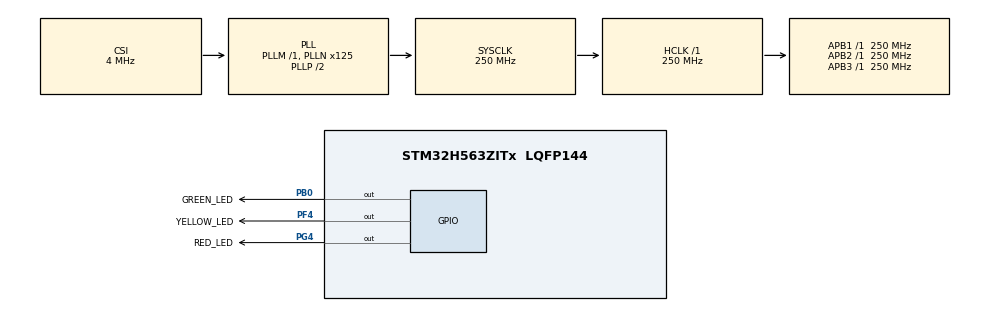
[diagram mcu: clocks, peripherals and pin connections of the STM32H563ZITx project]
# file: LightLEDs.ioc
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CORTEX_M33_NS.userName=CORTEX_M33
Mcu.Family=STM32H5
Mcu.Name=STM32H563ZITx
Mcu.Package=LQFP144
NVIC.PriorityGroup=NVIC_PRIORITYGROUP_4
PB0.GPIO_Label=GREEN_LED
PB0.Signal=GPIO_Output
PF4.GPIO_Label=YELLOW_LED
PF4.Signal=GPIO_Output
PG4.GPIO_Label=RED_LED
PG4.Signal=GPIO_Output
ProjectManager.HeapSize=0x200
ProjectManager.StackSize=0x400
ProjectManager.TargetToolchain=STM32CubeIDE
RCC.ADCFreq_Value=250000000
RCC.AHBFreq_Value=250000000
RCC.APB1Freq_Value=250000000
RCC.APB1TimFreq_Value=250000000
RCC.APB2Freq_Value=250000000
RCC.APB2TimFreq_Value=250000000
RCC.APB3Freq_Value=250000000
RCC.CSI_VALUE=4000000
RCC.CortexFreq_Value=250000000
RCC.EPOD_VALUE=4000000
RCC.HCLKFreq_Value=250000000
RCC.HSE_VALUE=25000000
RCC.HSI48_VALUE=48000000
RCC.HSI_VALUE=64000000
RCC.LSE_VALUE=32768
RCC.LSIRC_VALUE=32000
RCC.PLL2FRACN=0
RCC.PLL3FRACN=0
RCC.PLLFRACN=0
RCC.PLLN=125
RCC.SYSCLKFreq_VALUE=250000000
RCC.SYSCLKSource=RCC_SYSCLKSOURCE_PLLCLK
RCC.USBFreq_Value=48000000
RCC.VCOOutputFreq_Value=500000000
VP_BOOTPATH_VS_BOOTPATH.Mode=BP_Activate
VP_ICACHE_VS_ICACHE.Mode=DirectMappedCache
VP_MEMORYMAP_VS_MEMORYMAP.Mode=CurAppReg
VP_PWR_VS_DBSignals.Mode=DisableDeadBatterySignals
VP_PWR_VS_LPOM.Mode=PowerOptimisation
VP_PWR_VS_SECSignals.Mode=Security/Privilege
board=custom

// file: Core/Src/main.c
/* USER CODE BEGIN Header */
/**
 ******************************************************************************
 * @file           : main.c
 * @brief          : Main program body
 ******************************************************************************
 * @attention
 *
 * Copyright (c) 2023 STMicroelectronics.
 * All rights reserved.
 *
 * This software is licensed under terms that can be found in the LICENSE file
 * in the root directory of this software component.
 * If no LICENSE file comes with this software, it is provided AS-IS.
 *
 ******************************************************************************
 */
/* USER CODE END Header */
#include "main.h"
#include "icache.h"
#include "memorymap.h"
#include "gpio.h"

void SystemClock_Config(void);

int main(void)
{

  /* MCU Configuration--------------------------------------------------------*/

  /* Reset of all peripherals, Initializes the Flash interface and the Systick. */
  HAL_Init();

  /* Configure the system clock */
  SystemClock_Config();

  /* Initialize all configured peripherals */
  MX_GPIO_Init();
  MX_MEMORYMAP_Init();
  MX_ICACHE_Init();

  /* Infinite loop */
  /* USER CODE BEGIN WHILE */
	while (1)
	{
		HAL_GPIO_TogglePin(GREEN_LED_GPIO_Port, GREEN_LED_Pin);
		HAL_GPIO_TogglePin(YELLOW_LED_GPIO_Port, YELLOW_LED_Pin);
		HAL_GPIO_TogglePin(RED_LED_GPIO_Port, RED_LED_Pin);
		HAL_Delay(300);
    /* USER CODE END WHILE */

	}
}

void SystemClock_Config(void)
{
  RCC_OscInitTypeDef RCC_OscInitStruct = {0};
  RCC_ClkInitTypeDef RCC_ClkInitStruct = {0};

  /** Configure the main internal regulator output voltage
  */
  __HAL_PWR_VOLTAGESCALING_CONFIG(PWR_REGULATOR_VOLTAGE_SCALE0);

  while(!__HAL_PWR_GET_FLAG(PWR_FLAG_VOSRDY)) {}

  /** Initializes the RCC Oscillators according to the specified parameters
  * in the RCC_OscInitTypeDef structure.
  */
  RCC_OscInitStruct.OscillatorType = RCC_OSCILLATORTYPE_CSI;
  RCC_OscInitStruct.CSIState = RCC_CSI_ON;
  RCC_OscInitStruct.CSICalibrationValue = RCC_CSICALIBRATION_DEFAULT;
  RCC_OscInitStruct.PLL.PLLState = RCC_PLL_ON;
  RCC_OscInitStruct.PLL.PLLSource = RCC_PLL1_SOURCE_CSI;
  RCC_OscInitStruct.PLL.PLLM = 1;
  RCC_OscInitStruct.PLL.PLLN = 125;
  RCC_OscInitStruct.PLL.PLLP = 2;
  RCC_OscInitStruct.PLL.PLLQ = 2;
  RCC_OscInitStruct.PLL.PLLR = 2;
  RCC_OscInitStruct.PLL.PLLRGE = RCC_PLL1_VCIRANGE_2;
  RCC_OscInitStruct.PLL.PLLVCOSEL = RCC_PLL1_VCORANGE_WIDE;
  RCC_OscInitStruct.PLL.PLLFRACN = 0;
  if (HAL_RCC_OscConfig(&RCC_OscInitStruct) != HAL_OK)
  {
    Error_Handler();
  }

  /** Initializes the CPU, AHB and APB buses clocks
  */
  RCC_ClkInitStruct.ClockType = RCC_CLOCKTYPE_HCLK|RCC_CLOCKTYPE_SYSCLK
                              |RCC_CLOCKTYPE_PCLK1|RCC_CLOCKTYPE_PCLK2
                              |RCC_CLOCKTYPE_PCLK3;
  RCC_ClkInitStruct.SYSCLKSource = RCC_SYSCLKSOURCE_PLLCLK;
  RCC_ClkInitStruct.AHBCLKDivider = RCC_SYSCLK_DIV1;
  RCC_ClkInitStruct.APB1CLKDivider = RCC_HCLK_DIV1;
  RCC_ClkInitStruct.APB2CLKDivider = RCC_HCLK_DIV1;
  RCC_ClkInitStruct.APB3CLKDivider = RCC_HCLK_DIV1;

  if (HAL_RCC_ClockConfig(&RCC_ClkInitStruct, FLASH_LATENCY_5) != HAL_OK)
  {
    Error_Handler();
  }
}

void Error_Handler(void)
{
	__disable_irq();
	while (1)
	{
	}
}
